# ATSAM4LS2B register map
Vendor: Atmel Corporation; Series: SAM4L; File version: B
CPU: CM4 r0p1, little endian, MPU, no FPU, 4 interrupt priority bits
Registers are 32-bit, write-only, reset 0x0 unless marked. A register's access mark holds for its fields unless they carry their own. Offsets are from the block's base; [hi:lo] are bit positions; {n}, {i} and the like mark numbered series; 'fields as' and 'values as' point back to an identical list.

## TC0 — Timer/Counter 0
Base 0x40010000; register names take the prefix TC_
Same registers: TC1 0x40014000
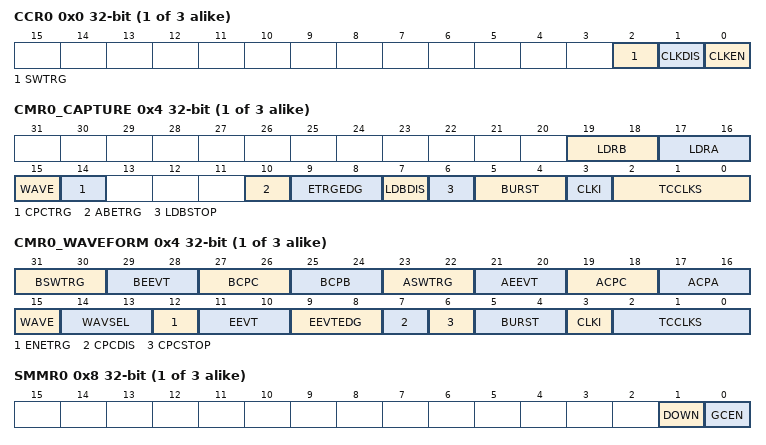
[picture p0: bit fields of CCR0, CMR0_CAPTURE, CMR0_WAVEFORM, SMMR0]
{0x0+0x40*i} CCR{i} (i=0..2) — Channel Control Register Channel
  [2] SWTRG — Software Trigger Command
    0=No effect; 1=A software trigger is performed:the counter is reset and clock is started
  [1] CLKDIS — Counter Clock Disable Command
    0=No effect; 1=Disables the clock
  [0] CLKEN — Counter Clock Enable Command
    0=No effect; 1=Enables the clock if CLKDIS is not 1
{0x4+0x40*i} CMR{i}_CAPTURE (i=0..2) rw (alternate view of CMR{i}) — Channel Mode Register Channel
  [19:18] LDRB — RB Loading Selection
    0=NO_EDGE (none); 1=POS_EDGE_TIOA (rising edge of TIOA); 2=NEG_EDGE_TIOA (falling edge of TIOA); 3=BOTH_EDGES_TIOA (each edge of TIOA)
  [17:16] LDRA — RA Loading Selection
    values as LDRB
  [15] WAVE
    0=Capture Mode is enabled; 1=Capture Mode is disabled (Waveform Mode is enabled)
  [14] CPCTRG — RC Compare Trigger Enable
    0=RC Compare has no effect on the counter and its clock; 1=RC Compare resets the counter and starts the counter clock
  [10] ABETRG — TIOA or TIOB External Trigger Selection
    0=TIOB is used as an external trigger; 1=TIOA is used as an external trigger
  [9:8] ETRGEDG — External Trigger Edge Selection
    0=NO_EDGE (none); 1=POS_EDGE (rising edge); 2=NEG_EDGE (falling edge); 3=BOTH_EDGES (each edge)
  [7] LDBDIS — Counter Clock Disable with RB Loading
    0=Counter clock is not disabled when RB loading occurs; 1=Counter clock is disabled when RB loading occurs
  [6] LDBSTOP — Counter Clock Stopped with RB Loading
    0=Counter clock is not stopped when RB loading occurs; 1=Counter clock is stopped when RB loading occurs
  [5:4] BURST — Burst Signal Selection
    0=NOT_GATED (The clock is not gated by an external signal.); 1=CLK_AND_XC0 (XC0 is ANDed with the selected clock.); 2=CLK_AND_XC1 (XC1 is ANDed with the selected clock.); 3=CLK_AND_XC2 (XC2 is ANDed with the selected clock.)
  [3] CLKI — Clock Invert
    0=Counter is incremented on rising edge of the clock; 1=Counter is incremented on falling edge of the clock
  [2:0] TCCLKS — Clock Selection
    {v}=TIMER_CLOCK{v+1} (v=0..4); 5=XC0; 6=XC1; 7=XC2
{0x4+0x40*i} CMR{i}_WAVEFORM (i=0..2) rw (alternate view of CMR{i}) — Channel Mode Register Channel
  [31:30] BSWTRG — Software Trigger Effect on TIOB
    0=NONE; 1=SET; 2=CLEAR; 3=TOGGLE
  [29:28] BEEVT — External Event Effect on TIOB
    0=NONE; 1=SET; 2=CLEAR; 3=TOGGLE
  [27:26] BCPC — RC Compare Effect on TIOB
    0=NONE; 1=SET; 2=CLEAR; 3=TOGGLE
  [25:24] BCPB — RB Compare Effect on TIOB
    0=NONE; 1=SET; 2=CLEAR; 3=TOGGLE
  [23:22] ASWTRG — Software Trigger Effect on TIOA
    0=NONE; 1=SET; 2=CLEAR; 3=TOGGLE
  [21:20] AEEVT — External Event Effect on TIOA
    0=NONE; 1=SET; 2=CLEAR; 3=TOGGLE
  [19:18] ACPC — RC Compare Effect on TIOA
    0=NONE; 1=SET; 2=CLEAR; 3=TOGGLE
  [17:16] ACPA — RA Compare Effect on TIOA
    0=NONE; 1=SET; 2=CLEAR; 3=TOGGLE
  [15] WAVE
    0=Waveform Mode is disabled (Capture Mode is enabled); 1=Waveform Mode is enabled
  [14:13] WAVSEL — Waveform Selection
    0=UP_NO_AUTO (UP mode without automatic trigger on RC Compare); 1=UPDOWN_NO_AUTO (UPDOWN mode without automatic trigger on RC Compare); 2=UP_AUTO (UP mode with automatic trigger on RC Compare); 3=UPDOWN_AUTO (UPDOWN mode with automatic trigger on RC Compare)
  [12] ENETRG — External Event Trigger Enable
    0=The external event has no effect on the counter and its clock. In this case, the selected external event only controls the TIOA output.; 1=The external event resets the counter and starts the counter clock
  [11:10] EEVT — External Event Selection
    0=TIOB_INPUT (TIOB input. If TIOB is chosen as the external event signal, it is configured as an input and no longer generates waveforms.); 1=XC0_OUTPUT; 2=XC1_OUTPUT; 3=XC2_OUTPUT
  [9:8] EEVTEDG — External Event Edge Selection
    values as CMR0_CAPTURE.ETRGEDG
  [7] CPCDIS — Counter Clock Disable with RC Compare
    0=Counter clock is not disabled when counter reaches RC; 1=Counter clock is disabled when counter reaches RC
  [6] CPCSTOP — Counter Clock Stopped with RC Compare
    0=Counter clock is not stopped when counter reaches RC; 1=Counter clock is stopped when counter reaches RC
  [5:4] BURST — Burst Signal Selection
    values as CMR0_CAPTURE.BURST
  [3] CLKI — Clock Invert
    values as CMR0_CAPTURE.CLKI
  [2:0] TCCLKS — Clock Selection
    {v}=TIMER_DIV{v+1}_CLOCK (v=0..4); 5=XC0; 6=XC1; 7=XC2
{0x8+0x40*i} SMMR{i} (i=0..2) rw — Stepper Motor Mode Register
  [1] DOWN — Down Count
  [0] GCEN — Gray Count Enable
{0x10+0x40*i} CV{i} (i=0..2) ro — Counter Value Channel
  [15:0] CV — Counter Value
{0x14+0x40*i} RA{i} (i=0..2) rw — Register A Channel
  [15:0] RA — Register A
{0x18+0x40*i} RB{i} (i=0..2) rw — Register B Channel
  [15:0] RB — Register B
{0x1C+0x40*i} RC{i} (i=0..2) rw — Register C Channel
  [15:0] RC — Register C
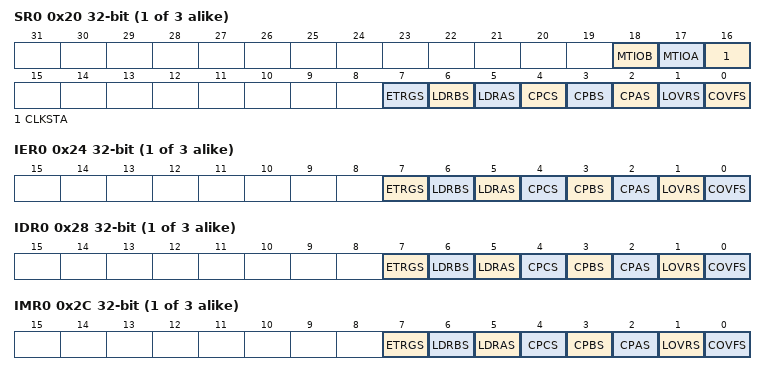
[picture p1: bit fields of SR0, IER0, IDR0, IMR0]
{0x20+0x40*i} SR{i} (i=0..2) ro — Status Register Channel
  [18] MTIOB — TIOB Mirror
    0=TIOB is low. If WAVE:0, this means that TIOB pin is low. If WAVE:1, this means that TIOB is driven low.; 1=TIOB is high. If WAVE:0, this means that TIOB pin is high. If WAVE:1, this means that TIOB is driven high.
  [17] MTIOA — TIOA Mirror
    0=TIOA is low. If WAVE:0, this means that TIOA pin is low. If WAVE:1, this means that TIOA is driven low.; 1=TIOA is high. If WAVE:0, this means that TIOA pin is high. If WAVE:1, this means that TIOA is driven high.
  [16] CLKSTA — Clock Enabling Status
    0=Clock is disabled; 1=Clock is enabled
  [7] ETRGS — External Trigger Status
    0=External trigger has not occurred since the last read of the Status Register; 1=External trigger has occurred since the last read of the Status Register
  [6] LDRBS — RB Loading Status
    0=RB Load has not occurred since the last read of the Status Register or WAVE:1; 1=RB Load has occurred since the last read of the Status Register, if WAVE:0
  [5] LDRAS — RA Loading Status
    0=RA Load has not occurred since the last read of the Status Register or WAVE:1; 1=RA Load has occurred since the last read of the Status Register, if WAVE:0
  [4] CPCS — RC Compare Status
    0=RC Compare has not occurred since the last read of the Status Register; 1=RC Compare has occurred since the last read of the Status Register
  [3] CPBS — RB Compare Status
    0=RB Compare has not occurred since the last read of the Status Register or WAVE:0; 1=RB Compare has occurred since the last read of the Status Register, if WAVE:1
  [2] CPAS — RA Compare Status
    0=RA Compare has not occurred since the last read of the Status Register or WAVE:0; 1=RA Compare has occurred since the last read of the Status Register, if WAVE:1
  [1] LOVRS — Load Overrun Status
    0=Load overrun has not occurred since the last read of the Status Register or WAVE:1; 1=RA or RB have been loaded at least twice without any read of the corresponding register since the last read of the StatusRegister, if WAVE:0
  [0] COVFS — Counter Overflow Status
    0=No counter overflow has occurred since the last read of the Status Register; 1=A counter overflow has occurred since the last read of the Status Register
{0x24+0x40*i} IER{i} (i=0..2) — Interrupt Enable Register Channel
  [7] ETRGS — External Trigger
    0=No effect; 1=Enables the External Trigger Interrupt
  [6] LDRBS — RB Loading
    0=No effect; 1=Enables the RB Load Interrupt
  [5] LDRAS — RA Loading
    0=No effect; 1=Enables the RA Load Interrupt
  [4] CPCS — RC Compare
    0=No effect; 1=Enables the RC Compare Interrupt
  [3] CPBS — RB Compare
    0=No effect; 1=Enables the RB Compare Interrupt
  [2] CPAS — RA Compare
    0=No effect; 1=Enables the RA Compare Interrupt
  [1] LOVRS — Load Overrun
    0=No effect; 1=Enables the Load Overrun Interrupt
  [0] COVFS — Counter Overflow
    0=No effect; 1=Enables the Counter Overflow Interrupt
{0x28+0x40*i} IDR{i} (i=0..2) — Interrupt Disable Register Channel
  [7] ETRGS — External Trigger
    0=No effect; 1=Disables the External Trigger Interrupt
  [6] LDRBS — RB Loading
    0=No effect; 1=Disables the RB Load Interrupt (if WAVE:0)
  [5] LDRAS — RA Loading
    0=No effect; 1=Disables the RA Load Interrupt (if WAVE:0)
  [4] CPCS — RC Compare
    0=No effect; 1=Disables the RC Compare Interrupt
  [3] CPBS — RB Compare
    0=No effect; 1=Disables the RB Compare Interrupt (if WAVE:1)
  [2] CPAS — RA Compare
    0=No effect; 1=Disables the RA Compare Interrupt (if WAVE:1)
  [1] LOVRS — Load Overrun
    0=No effect; 1=Disables the Load Overrun Interrupt (if WAVE:0)
  [0] COVFS — Counter Overflow
    0=No effect; 1=Disables the Counter Overflow Interrupt
{0x2C+0x40*i} IMR{i} (i=0..2) ro — Interrupt Mask Register Channel
  [7] ETRGS — External Trigger
    0=The External Trigger Interrupt is disabled; 1=The External Trigger Interrupt is enabled
  [6] LDRBS — RB Loading
    0=The Load RB Interrupt is disabled; 1=The Load RB Interrupt is enabled
  [5] LDRAS — RA Loading
    0=The Load RA Interrupt is disabled; 1=The Load RA Interrupt is enabled
  [4] CPCS — RC Compare
    0=The RC Compare Interrupt is disabled; 1=The RC Compare Interrupt is enabled
  [3] CPBS — RB Compare
    0=The RB Compare Interrupt is disabled; 1=The RB Compare Interrupt is enabled
  [2] CPAS — RA Compare
    0=The RA Compare Interrupt is disabled; 1=The RA Compare Interrupt is enabled
  [1] LOVRS — Load Overrun
    0=The Load Overrun Interrupt is disabled; 1=The Load Overrun Interrupt is enabled
  [0] COVFS — Counter Overflow
    0=The Counter Overflow Interrupt is disabled; 1=The Counter Overflow Interrupt is enabled
0xC0 BCR — TC Block Control Register
  [0] SYNC — Synchro Command
    0=No effect; 1=Asserts the SYNC signal which generates a software trigger simultaneously for each of the channels
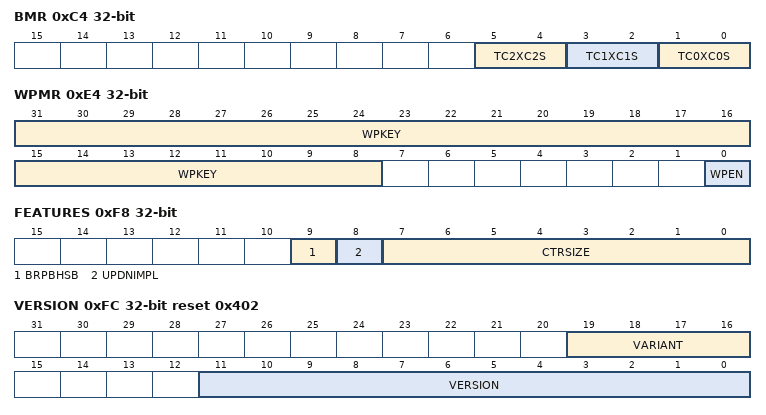
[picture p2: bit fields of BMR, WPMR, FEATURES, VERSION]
0xC4 BMR rw — TC Block Mode Register
  [5:4] TC2XC2S — External Clock Signal 2 Selection
    0=TCLK2 (Select TCLK2 as clock signal 2.); 1=NO_CLK (Select no clock as clock signal 2.); 2=TIOA0 (Select TIOA0 as clock signal 2.); 3=TIOA1 (Select TIOA1 as clock signal 2.)
  [3:2] TC1XC1S — External Clock Signal 1 Selection
    0=TCLK1 (Select TCLK1 as clock signal 1.); 1=NO_CLK (Select no clock as clock signal 1.); 2=TIOA0 (Select TIOA0 as clock signal 1.); 3=TIOA2 (Select TIOA2 as clock signal 1.)
  [1:0] TC0XC0S — External Clock Signal 0 Selection
    0=TCLK0 (Select TCLK0 as clock signal 0.); 1=NO_CLK (Select no clock as clock signal 0.); 2=TIOA1 (Select TIOA1 as clock signal 0.); 3=TIOA2 (Select TIOA2 as clock signal 0.)
0xE4 WPMR rw — Write Protect Mode Register
  [31:8] WPKEY — Write Protect Key
  [0] WPEN — Write Protect Enable
0xF8 FEATURES ro
  [9] BRPBHSB — Bridge Type is PB to HSB
  [8] UPDNIMPL — Up Down is Implemented
  [7:0] CTRSIZE — Counter Size
0xFC VERSION ro reset 0x402
  [19:16] VARIANT — Reserved. Value subject to change. No functionality associated.
  [11:0] VERSION — Reserved. Value subject to change. No functionality associated. This is the Atmel internal version of the macrocell.

## Notices in the file
Atmel Microcontroller Software Support
Copyright (c) 2016 Atmel Corporation,
a wholly owned subsidiary of Microchip Technology Inc.
Licensed under the Apache License, Version 2.0 (the "License");
you may not use this file except in compliance with the License.
You may obtain a copy of the Licence at
http://www.apache.org/licenses/LICENSE-2.0
Unless required by applicable law or agreed to in writing, software
distributed under the License is distributed on an "AS IS" BASIS,
WITHOUT WARRANTIES OR CONDITIONS OF ANY KIND, either express or implied.
See the License for the specific language governing permissions and
limitations under the License.
